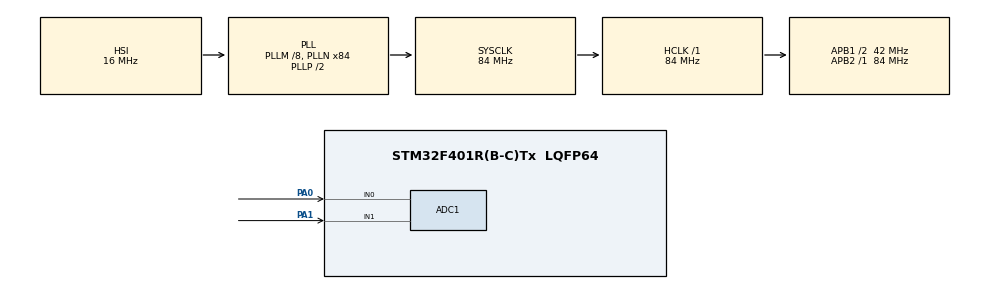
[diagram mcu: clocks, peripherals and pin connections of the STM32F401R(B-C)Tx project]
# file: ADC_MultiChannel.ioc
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ADC1.Channel-0\#ChannelRegularConversion=ADC_CHANNEL_0
ADC1.Channel-1\#ChannelRegularConversion=ADC_CHANNEL_1
ADC1.ContinuousConvMode=DISABLE
ADC1.DMAContinuousRequests=DISABLE
ADC1.EOCSelection=ADC_EOC_SEQ_CONV
ADC1.NbrOfConversion=2
ADC1.NbrOfConversionFlag=1
ADC1.Rank-0\#ChannelRegularConversion=1
ADC1.Rank-1\#ChannelRegularConversion=2
ADC1.SamplingTime-0\#ChannelRegularConversion=ADC_SAMPLETIME_84CYCLES
ADC1.SamplingTime-1\#ChannelRegularConversion=ADC_SAMPLETIME_84CYCLES
ADC1.ScanConvMode=ENABLE
ADC1.master=1
Dma.ADC1.0.Direction=DMA_PERIPH_TO_MEMORY
Dma.ADC1.0.FIFOMode=DMA_FIFOMODE_DISABLE
Dma.ADC1.0.Instance=DMA2_Stream0
Dma.ADC1.0.MemDataAlignment=DMA_MDATAALIGN_HALFWORD
Dma.ADC1.0.MemInc=DMA_MINC_ENABLE
Dma.ADC1.0.Mode=DMA_NORMAL
Dma.ADC1.0.PeriphDataAlignment=DMA_PDATAALIGN_HALFWORD
Dma.ADC1.0.PeriphInc=DMA_PINC_DISABLE
Dma.ADC1.0.Priority=DMA_PRIORITY_LOW
Dma.Request0=ADC1
Mcu.Family=STM32F4
Mcu.Name=STM32F401R(B-C)Tx
Mcu.Package=LQFP64
NVIC.ADC_IRQn=true\:1\:0\:true\:false\:true\:true\:true\:true
NVIC.DMA2_Stream0_IRQn=true\:0\:0\:false\:false\:true\:false\:true\:true
NVIC.PriorityGroup=NVIC_PRIORITYGROUP_4
PA0-WKUP.Signal=ADCx_IN0
PA1.Signal=ADCx_IN1
ProjectManager.HeapSize=0x200
ProjectManager.StackSize=0x400
ProjectManager.TargetToolchain=STM32CubeIDE
RCC.48MHZClocksFreq_Value=42000000
RCC.AHBFreq_Value=84000000
RCC.APB1CLKDivider=RCC_HCLK_DIV2
RCC.APB1Freq_Value=42000000
RCC.APB1TimFreq_Value=84000000
RCC.APB2Freq_Value=84000000
RCC.APB2TimFreq_Value=84000000
RCC.CortexFreq_Value=84000000
RCC.HCLKFreq_Value=84000000
RCC.HSE_VALUE=25000000
RCC.HSI_VALUE=16000000
RCC.LSE_VALUE=32768
RCC.PLLM=8
RCC.PLLN=84
RCC.SYSCLKFreq_VALUE=84000000
RCC.SYSCLKSource=RCC_SYSCLKSOURCE_PLLCLK
RCC.VCOOutputFreq_Value=168000000
SH.ADCx_IN0.0=ADC1_IN0,IN0
SH.ADCx_IN1.0=ADC1_IN1,IN1
board=custom

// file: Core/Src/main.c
/* USER CODE BEGIN Header */
/**
  ******************************************************************************
  * @file           : main.c
  * @brief          : Main program body
  ******************************************************************************
  * @attention
  *
  * Copyright (c) 2025 STMicroelectronics.
  * All rights reserved.
  *
  * This software is licensed under terms that can be found in the LICENSE file
  * in the root directory of this software component.
  * If no LICENSE file comes with this software, it is provided AS-IS.
  *
  ******************************************************************************
  */
/* USER CODE END Header */
#include "main.h"
#include "adc.h"
#include "dma.h"
#include "gpio.h"

/* USER CODE BEGIN PV */
uint16_t adc_value1, adc_value2;
uint16_t raw_data[2];
uint8_t conversion_complete = 0;
/* USER CODE END PV */

void SystemClock_Config(void);
/* USER CODE BEGIN PFP */
void HAL_ADC_ConvCpltCallback(ADC_HandleTypeDef *hadc)
{
	conversion_complete = 1;
}
/* USER CODE END PFP */

int main(void)
{

  /* MCU Configuration--------------------------------------------------------*/

  /* Reset of all peripherals, Initializes the Flash interface and the Systick. */
  HAL_Init();

  /* Configure the system clock */
  SystemClock_Config();

  /* Initialize all configured peripherals */
  MX_GPIO_Init();
  MX_DMA_Init();
  MX_ADC1_Init();
  /* USER CODE BEGIN 2 */
//  HAL_ADC_Start_DMA(&hadc1, (uint32_t*) raw_data, 2);
  /* USER CODE END 2 */

  /* Infinite loop */
  while (1)
  {

    /* USER CODE BEGIN 3 */
	  HAL_ADC_Start_DMA(&hadc1, (uint32_t*) raw_data, 2);
	  while(!conversion_complete);
	  conversion_complete = 0;
	  adc_value1 = raw_data[0];
	  adc_value2 = raw_data[1];

  }
  /* USER CODE END 3 */
}

void SystemClock_Config(void)
{
  RCC_OscInitTypeDef RCC_OscInitStruct = {0};
  RCC_ClkInitTypeDef RCC_ClkInitStruct = {0};

  /** Configure the main internal regulator output voltage
  */
  __HAL_RCC_PWR_CLK_ENABLE();
  __HAL_PWR_VOLTAGESCALING_CONFIG(PWR_REGULATOR_VOLTAGE_SCALE2);

  /** Initializes the RCC Oscillators according to the specified parameters
  * in the RCC_OscInitTypeDef structure.
  */
  RCC_OscInitStruct.OscillatorType = RCC_OSCILLATORTYPE_HSI;
  RCC_OscInitStruct.HSIState = RCC_HSI_ON;
  RCC_OscInitStruct.HSICalibrationValue = RCC_HSICALIBRATION_DEFAULT;
  RCC_OscInitStruct.PLL.PLLState = RCC_PLL_ON;
  RCC_OscInitStruct.PLL.PLLSource = RCC_PLLSOURCE_HSI;
  RCC_OscInitStruct.PLL.PLLM = 8;
  RCC_OscInitStruct.PLL.PLLN = 84;
  RCC_OscInitStruct.PLL.PLLP = RCC_PLLP_DIV2;
  RCC_OscInitStruct.PLL.PLLQ = 4;
  if (HAL_RCC_OscConfig(&RCC_OscInitStruct) != HAL_OK)
  {
    Error_Handler();
  }

  /** Initializes the CPU, AHB and APB buses clocks
  */
  RCC_ClkInitStruct.ClockType = RCC_CLOCKTYPE_HCLK|RCC_CLOCKTYPE_SYSCLK
                              |RCC_CLOCKTYPE_PCLK1|RCC_CLOCKTYPE_PCLK2;
  RCC_ClkInitStruct.SYSCLKSource = RCC_SYSCLKSOURCE_PLLCLK;
  RCC_ClkInitStruct.AHBCLKDivider = RCC_SYSCLK_DIV1;
  RCC_ClkInitStruct.APB1CLKDivider = RCC_HCLK_DIV2;
  RCC_ClkInitStruct.APB2CLKDivider = RCC_HCLK_DIV1;

  if (HAL_RCC_ClockConfig(&RCC_ClkInitStruct, FLASH_LATENCY_2) != HAL_OK)
  {
    Error_Handler();
  }
}

void Error_Handler(void)
{
  __disable_irq();
  while (1)
  {
  }
}
